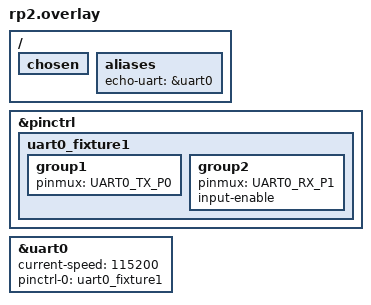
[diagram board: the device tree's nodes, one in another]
/* SPDX-License-Identifier: Apache-2.0 OR MIT */

/ {
	chosen {
		/delete-property/ zephyr,console;
		/delete-property/ zephyr,shell-uart;
	};

	aliases {
		echo-uart = &uart0;
	};
};

&pinctrl {
	uart0_fixture1: uart0_fixture1 {
		group1 {
			pinmux = <UART0_TX_P0>;
		};
		group2 {
			pinmux = <UART0_RX_P1>;
			input-enable;
		};
	};
};

/*
 * The fixture's crossed pair, the DUT's console UART: the DUT's GP0 drives
 * the harness's GP1 and the harness's GP0 drives the DUT's GP1. The image
 * echoes everything it receives here.
 */
&uart0 {
	status = "okay";
	current-speed = <115200>;
	pinctrl-0 = <&uart0_fixture1>;
	pinctrl-names = "default";
};
